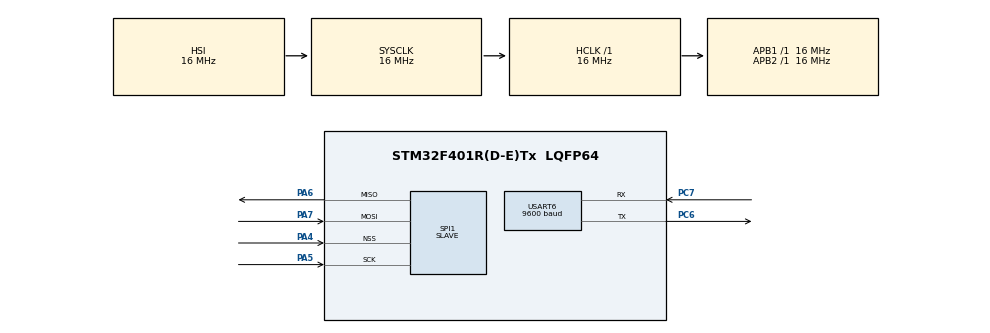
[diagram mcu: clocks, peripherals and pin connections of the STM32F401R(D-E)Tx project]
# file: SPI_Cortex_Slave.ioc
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Dma.Request0=USART6_TX
Dma.Request1=USART6_RX
Dma.Request2=SPI1_RX
Dma.Request3=SPI1_TX
Dma.SPI1_RX.2.Direction=DMA_PERIPH_TO_MEMORY
Dma.SPI1_RX.2.FIFOMode=DMA_FIFOMODE_DISABLE
Dma.SPI1_RX.2.Instance=DMA2_Stream0
Dma.SPI1_RX.2.MemDataAlignment=DMA_MDATAALIGN_BYTE
Dma.SPI1_RX.2.MemInc=DMA_MINC_ENABLE
Dma.SPI1_RX.2.Mode=DMA_CIRCULAR
Dma.SPI1_RX.2.PeriphDataAlignment=DMA_PDATAALIGN_BYTE
Dma.SPI1_RX.2.PeriphInc=DMA_PINC_DISABLE
Dma.SPI1_RX.2.Priority=DMA_PRIORITY_LOW
Dma.SPI1_TX.3.Direction=DMA_MEMORY_TO_PERIPH
Dma.SPI1_TX.3.FIFOMode=DMA_FIFOMODE_DISABLE
Dma.SPI1_TX.3.Instance=DMA2_Stream3
Dma.SPI1_TX.3.MemDataAlignment=DMA_MDATAALIGN_BYTE
Dma.SPI1_TX.3.MemInc=DMA_MINC_ENABLE
Dma.SPI1_TX.3.Mode=DMA_CIRCULAR
Dma.SPI1_TX.3.PeriphDataAlignment=DMA_PDATAALIGN_BYTE
Dma.SPI1_TX.3.PeriphInc=DMA_PINC_DISABLE
Dma.SPI1_TX.3.Priority=DMA_PRIORITY_LOW
Dma.USART6_RX.1.Direction=DMA_PERIPH_TO_MEMORY
Dma.USART6_RX.1.FIFOMode=DMA_FIFOMODE_DISABLE
Dma.USART6_RX.1.Instance=DMA2_Stream1
Dma.USART6_RX.1.MemDataAlignment=DMA_MDATAALIGN_BYTE
Dma.USART6_RX.1.MemInc=DMA_MINC_ENABLE
Dma.USART6_RX.1.Mode=DMA_CIRCULAR
Dma.USART6_RX.1.PeriphDataAlignment=DMA_PDATAALIGN_BYTE
Dma.USART6_RX.1.PeriphInc=DMA_PINC_DISABLE
Dma.USART6_RX.1.Priority=DMA_PRIORITY_LOW
Dma.USART6_TX.0.Direction=DMA_MEMORY_TO_PERIPH
Dma.USART6_TX.0.FIFOMode=DMA_FIFOMODE_DISABLE
Dma.USART6_TX.0.Instance=DMA2_Stream6
Dma.USART6_TX.0.MemDataAlignment=DMA_MDATAALIGN_BYTE
Dma.USART6_TX.0.MemInc=DMA_MINC_ENABLE
Dma.USART6_TX.0.Mode=DMA_CIRCULAR
Dma.USART6_TX.0.PeriphDataAlignment=DMA_PDATAALIGN_BYTE
Dma.USART6_TX.0.PeriphInc=DMA_PINC_DISABLE
Dma.USART6_TX.0.Priority=DMA_PRIORITY_LOW
Mcu.Family=STM32F4
Mcu.Name=STM32F401R(D-E)Tx
Mcu.Package=LQFP64
NVIC.DMA2_Stream0_IRQn=true\:0\:0\:false\:true\:true\:1\:false
NVIC.DMA2_Stream1_IRQn=true\:0\:0\:false\:false\:true\:false
NVIC.DMA2_Stream3_IRQn=true\:0\:0\:false\:false\:true\:false
NVIC.DMA2_Stream6_IRQn=true\:0\:0\:false\:false\:true\:false
NVIC.PriorityGroup=NVIC_PRIORITYGROUP_4
NVIC.SPI1_IRQn=true\:0\:0\:false\:false\:true\:true
NVIC.USART6_IRQn=true\:0\:0\:false\:false\:true\:true
PA4.Mode=NSS_Signal_Hard_Input
PA4.Signal=SPI1_NSS
PA5.Mode=Full_Duplex_Slave
PA5.Signal=SPI1_SCK
PA6.Mode=Full_Duplex_Slave
PA6.Signal=SPI1_MISO
PA7.Mode=Full_Duplex_Slave
PA7.Signal=SPI1_MOSI
PC6.Mode=Asynchronous
PC6.Signal=USART6_TX
PC7.Mode=Asynchronous
PC7.Signal=USART6_RX
ProjectManager.HeapSize=0x200
ProjectManager.StackSize=0x400
ProjectManager.TargetToolchain=EWARM
RCC.AHBFreq_Value=16000000
RCC.APB1Freq_Value=16000000
RCC.APB2Freq_Value=16000000
RCC.CortexFreq_Value=16000000
RCC.HSE_VALUE=25000000
RCC.HSI_VALUE=16000000
RCC.LSE_VALUE=32768
RCC.SYSCLKFreq_VALUE=16000000
RCC.VCOOutputFreq_Value=192000000
SPI1.Direction=SPI_DIRECTION_2LINES
SPI1.Mode=SPI_MODE_SLAVE
SPI1.VirtualNSS=VM_NSSHARD
SPI1.VirtualType=VM_SLAVE
USART6.BaudRate=9600
USART6.VirtualMode=VM_ASYNC
board=SPI_Cortex_Slave

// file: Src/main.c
/**
  ******************************************************************************
  * @file           : main.c
  * @brief          : Main program body
  ******************************************************************************
  ** This notice applies to any and all portions of this file
  * that are not between comment pairs USER CODE BEGIN and
  * USER CODE END. Other portions of this file, whether
  * inserted by the user or by software development tools
  * are owned by their respective copyright owners.
  *
  * COPYRIGHT(c) 2020 STMicroelectronics
  *
  * Redistribution and use in source and binary forms, with or without modification,
  * are permitted provided that the following conditions are met:
  *   1. Redistributions of source code must retain the above copyright notice,
  *      this list of conditions and the following disclaimer.
  *   2. Redistributions in binary form must reproduce the above copyright notice,
  *      this list of conditions and the following disclaimer in the documentation
  *      and/or other materials provided with the distribution.
  *   3. Neither the name of STMicroelectronics nor the names of its contributors
  *      may be used to endorse or promote products derived from this software
  *      without specific prior written permission.
  *
  * THIS SOFTWARE IS PROVIDED BY THE COPYRIGHT HOLDERS AND CONTRIBUTORS "AS IS"
  * AND ANY EXPRESS OR IMPLIED WARRANTIES, INCLUDING, BUT NOT LIMITED TO, THE
  * IMPLIED WARRANTIES OF MERCHANTABILITY AND FITNESS FOR A PARTICULAR PURPOSE ARE
  * DISCLAIMED. IN NO EVENT SHALL THE COPYRIGHT HOLDER OR CONTRIBUTORS BE LIABLE
  * FOR ANY DIRECT, INDIRECT, INCIDENTAL, SPECIAL, EXEMPLARY, OR CONSEQUENTIAL
  * DAMAGES (INCLUDING, BUT NOT LIMITED TO, PROCUREMENT OF SUBSTITUTE GOODS OR
  * SERVICES; LOSS OF USE, DATA, OR PROFITS; OR BUSINESS INTERRUPTION) HOWEVER
  * CAUSED AND ON ANY THEORY OF LIABILITY, WHETHER IN CONTRACT, STRICT LIABILITY,
  * OR TORT (INCLUDING NEGLIGENCE OR OTHERWISE) ARISING IN ANY WAY OUT OF THE USE
  * OF THIS SOFTWARE, EVEN IF ADVISED OF THE POSSIBILITY OF SUCH DAMAGE.
  *
  ******************************************************************************
  */
#include "main.h"
#include "stm32f4xx_hal.h"

SPI_HandleTypeDef hspi1;
DMA_HandleTypeDef hdma_spi1_rx;
DMA_HandleTypeDef hdma_spi1_tx;

UART_HandleTypeDef huart6;
DMA_HandleTypeDef hdma_usart6_tx;
DMA_HandleTypeDef hdma_usart6_rx;

/* USER CODE BEGIN PV */
/* Private variables ---------------------------------------------------------*/
uint8_t TxData[7] = {1,0,2,4,5,1,5};
uint8_t RxData[7];
uint8_t Uart_RxData[7];

/* USER CODE END PV */

void SystemClock_Config(void);
static void MX_GPIO_Init(void);
static void MX_DMA_Init(void);
static void MX_SPI1_Init(void);
static void MX_USART6_UART_Init(void);
static void MX_NVIC_Init(void);

/* USER CODE BEGIN PFP */
/* Private function prototypes -----------------------------------------------*/

/* USER CODE END PFP */

/* USER CODE BEGIN 0 */
void HAL_SPI_RxCpltCallback(SPI_HandleTypeDef *hspi1){
}
/* USER CODE END 0 */

int main(void)
{

  /* MCU Configuration----------------------------------------------------------*/

  /* Reset of all peripherals, Initializes the Flash interface and the Systick. */
  HAL_Init();

  /* Configure the system clock */
  SystemClock_Config();

  /* Initialize all configured peripherals */
  MX_GPIO_Init();
  MX_DMA_Init();
  MX_SPI1_Init();
  MX_USART6_UART_Init();

  /* Initialize interrupts */
  MX_NVIC_Init();
  /* USER CODE BEGIN 2 */
  HAL_SPI_TransmitReceive_DMA(&hspi1, TxData, RxData, 7);
  HAL_UART_Receive_DMA(&huart6, Uart_RxData, 7);
//  u8g_InitComFn(&u8g, &u8g_dev_ssd1306_128x64_hw_spi, u8g_com_hw_spi_fn);
  HAL_Delay(100);
  /* USER CODE END 2 */

  /* Infinite loop */
  while (1)
  {

  /* USER CODE BEGIN 3 */
//    u8g_FirstPage(&u8g);
//       do
//       {
//            u8g.font = u8g_font_profont22;
//            u8g_DrawStr(&u8g, 20, 55, "Hello");
//       } while ( u8g_NextPage(&u8g) );
//    HAL_Delay(100);

    /* Warning!! hc-12 model needs 3.3v to operate */
//    HAL_UART_Transmit(&huart6, RxData, 7, 50);
//    HAL_UART_Transmit(&huart6, "\n", 1, 50);
//    HAL_Delay(10);
 //   Uart_Transmit(&huart6,RxData,7,50);
  }
  /* USER CODE END 3 */

}

void SystemClock_Config(void)
{

  RCC_OscInitTypeDef RCC_OscInitStruct;
  RCC_ClkInitTypeDef RCC_ClkInitStruct;

    /**Configure the main internal regulator output voltage
    */
  __HAL_RCC_PWR_CLK_ENABLE();

  __HAL_PWR_VOLTAGESCALING_CONFIG(PWR_REGULATOR_VOLTAGE_SCALE2);

    /**Initializes the CPU, AHB and APB busses clocks
    */
  RCC_OscInitStruct.OscillatorType = RCC_OSCILLATORTYPE_HSI;
  RCC_OscInitStruct.HSIState = RCC_HSI_ON;
  RCC_OscInitStruct.HSICalibrationValue = 16;
  RCC_OscInitStruct.PLL.PLLState = RCC_PLL_NONE;
  if (HAL_RCC_OscConfig(&RCC_OscInitStruct) != HAL_OK)
  {
    _Error_Handler(__FILE__, __LINE__);
  }

    /**Initializes the CPU, AHB and APB busses clocks
    */
  RCC_ClkInitStruct.ClockType = RCC_CLOCKTYPE_HCLK|RCC_CLOCKTYPE_SYSCLK
                              |RCC_CLOCKTYPE_PCLK1|RCC_CLOCKTYPE_PCLK2;
  RCC_ClkInitStruct.SYSCLKSource = RCC_SYSCLKSOURCE_HSI;
  RCC_ClkInitStruct.AHBCLKDivider = RCC_SYSCLK_DIV1;
  RCC_ClkInitStruct.APB1CLKDivider = RCC_HCLK_DIV1;
  RCC_ClkInitStruct.APB2CLKDivider = RCC_HCLK_DIV1;

  if (HAL_RCC_ClockConfig(&RCC_ClkInitStruct, FLASH_LATENCY_0) != HAL_OK)
  {
    _Error_Handler(__FILE__, __LINE__);
  }

    /**Configure the Systick interrupt time
    */
  HAL_SYSTICK_Config(HAL_RCC_GetHCLKFreq()/1000);

    /**Configure the Systick
    */
  HAL_SYSTICK_CLKSourceConfig(SYSTICK_CLKSOURCE_HCLK);

  /* SysTick_IRQn interrupt configuration */
  HAL_NVIC_SetPriority(SysTick_IRQn, 0, 0);
}

/**
  * @brief NVIC Configuration.
  * @retval None
  */
static void MX_NVIC_Init(void)
{
  /* DMA2_Stream0_IRQn interrupt configuration */
  HAL_NVIC_SetPriority(DMA2_Stream0_IRQn, 0, 0);
  HAL_NVIC_EnableIRQ(DMA2_Stream0_IRQn);
}

/* SPI1 init function */
static void MX_SPI1_Init(void)
{

  /* SPI1 parameter configuration*/
  hspi1.Instance = SPI1;
  hspi1.Init.Mode = SPI_MODE_SLAVE;
  hspi1.Init.Direction = SPI_DIRECTION_2LINES;
  hspi1.Init.DataSize = SPI_DATASIZE_8BIT;
  hspi1.Init.CLKPolarity = SPI_POLARITY_LOW;
  hspi1.Init.CLKPhase = SPI_PHASE_1EDGE;
  hspi1.Init.NSS = SPI_NSS_HARD_INPUT;
  hspi1.Init.FirstBit = SPI_FIRSTBIT_MSB;
  hspi1.Init.TIMode = SPI_TIMODE_DISABLE;
  hspi1.Init.CRCCalculation = SPI_CRCCALCULATION_DISABLE;
  hspi1.Init.CRCPolynomial = 10;
  if (HAL_SPI_Init(&hspi1) != HAL_OK)
  {
    _Error_Handler(__FILE__, __LINE__);
  }

}

/* USART6 init function */
static void MX_USART6_UART_Init(void)
{

  huart6.Instance = USART6;
  huart6.Init.BaudRate = 9600;
  huart6.Init.WordLength = UART_WORDLENGTH_8B;
  huart6.Init.StopBits = UART_STOPBITS_1;
  huart6.Init.Parity = UART_PARITY_NONE;
  huart6.Init.Mode = UART_MODE_TX_RX;
  huart6.Init.HwFlowCtl = UART_HWCONTROL_NONE;
  huart6.Init.OverSampling = UART_OVERSAMPLING_16;
  if (HAL_UART_Init(&huart6) != HAL_OK)
  {
    _Error_Handler(__FILE__, __LINE__);
  }

}

static void MX_DMA_Init(void)
{
  /* DMA controller clock enable */
  __HAL_RCC_DMA2_CLK_ENABLE();

  /* DMA interrupt init */
  /* DMA2_Stream1_IRQn interrupt configuration */
  HAL_NVIC_SetPriority(DMA2_Stream1_IRQn, 0, 0);
  HAL_NVIC_EnableIRQ(DMA2_Stream1_IRQn);
  /* DMA2_Stream3_IRQn interrupt configuration */
  HAL_NVIC_SetPriority(DMA2_Stream3_IRQn, 0, 0);
  HAL_NVIC_EnableIRQ(DMA2_Stream3_IRQn);
  /* DMA2_Stream6_IRQn interrupt configuration */
  HAL_NVIC_SetPriority(DMA2_Stream6_IRQn, 0, 0);
  HAL_NVIC_EnableIRQ(DMA2_Stream6_IRQn);

}

/** Pinout Configuration
*/
static void MX_GPIO_Init(void)
{

  /* GPIO Ports Clock Enable */
  __HAL_RCC_GPIOA_CLK_ENABLE();
  __HAL_RCC_GPIOC_CLK_ENABLE();

}

void _Error_Handler(char *file, int line)
{
  while(1)
  {
  }
}

/************************ (C) COPYRIGHT STMicroelectronics *****END OF FILE****/
